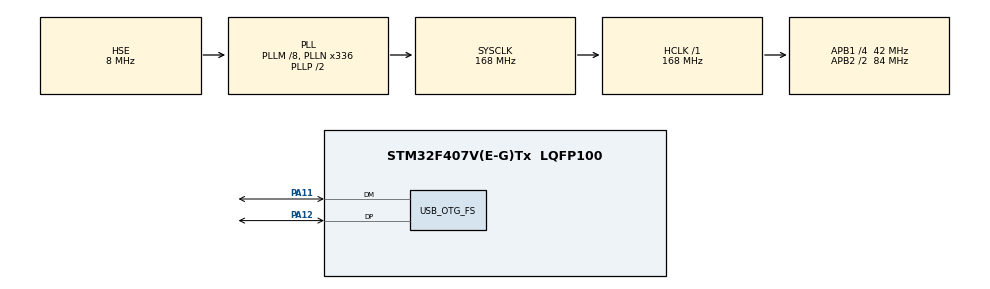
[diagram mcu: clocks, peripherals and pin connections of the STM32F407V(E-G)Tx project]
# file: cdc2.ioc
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Mcu.Family=STM32F4
Mcu.Name=STM32F407V(E-G)Tx
Mcu.Package=LQFP100
NVIC.OTG_FS_IRQn=true\:0\:0\:false\:false\:true\:true\:true
NVIC.PriorityGroup=NVIC_PRIORITYGROUP_0
PA11.Mode=Device_Only
PA11.Signal=USB_OTG_FS_DM
PA12.Mode=Device_Only
PA12.Signal=USB_OTG_FS_DP
PH0-OSC_IN.Mode=HSE-External-Oscillator
PH0-OSC_IN.Signal=RCC_OSC_IN
PH1-OSC_OUT.Mode=HSE-External-Oscillator
PH1-OSC_OUT.Signal=RCC_OSC_OUT
ProjectManager.HeapSize=0x400
ProjectManager.StackSize=0x600
ProjectManager.TargetToolchain=STM32CubeIDE
RCC.48MHZClocksFreq_Value=48000000
RCC.AHBFreq_Value=168000000
RCC.APB1CLKDivider=RCC_HCLK_DIV4
RCC.APB1Freq_Value=42000000
RCC.APB1TimFreq_Value=84000000
RCC.APB2CLKDivider=RCC_HCLK_DIV2
RCC.APB2Freq_Value=84000000
RCC.APB2TimFreq_Value=168000000
RCC.CortexFreq_Value=168000000
RCC.HCLKFreq_Value=168000000
RCC.HSE_VALUE=8000000
RCC.HSI_VALUE=16000000
RCC.PLLM=8
RCC.PLLN=336
RCC.PLLQ=7
RCC.SYSCLKFreq_VALUE=168000000
RCC.SYSCLKSource=RCC_SYSCLKSOURCE_PLLCLK
RCC.VCOOutputFreq_Value=336000000
USB_DEVICE.CLASS_NAME_FS=CDC
USB_DEVICE.VirtualMode-CDC_FS=Cdc
USB_DEVICE.VirtualModeFS=Cdc_FS
USB_OTG_FS.VirtualMode=Device_Only
VP_USB_DEVICE_VS_USB_DEVICE_CDC_FS.Mode=CDC_FS
board=STM32F407G-DISC1

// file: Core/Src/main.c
/* USER CODE BEGIN Header */
/**
  ******************************************************************************
  * @file           : main.c
  * @brief          : Main program body
  ******************************************************************************
  * @attention
  *
  * <h2><center>&copy; Copyright (c) 2020 STMicroelectronics.
  * All rights reserved.</center></h2>
  *
  * This software component is licensed by ST under Ultimate Liberty license
  * SLA0044, the "License"; You may not use this file except in compliance with
  * the License. You may obtain a copy of the License at:
  *                             www.st.com/SLA0044
  *
  ******************************************************************************
  */
/* USER CODE END Header */
#include "main.h"
#include "usb_device.h"
#include "ringbuffer.h"

/* USER CODE BEGIN Includes */
#include <string.h>

#include "usbd_cdc_if.h"
/* USER CODE END Includes */

void SystemClock_Config(void);
static void MX_GPIO_Init(void);

/* USER CODE BEGIN 0 */
uint8_t Buf[20]="momo world\r\n";

RingBuffer txBuf, rxBuf;
uint8_t  *txData;

/* USER CODE END 0 */

int main(void)
{

  /* MCU Configuration--------------------------------------------------------*/

  /* Reset of all peripherals, Initializes the Flash interface and the Systick. */
  HAL_Init();

  /* Configure the system clock */
  SystemClock_Config();

  /* Initialize all configured peripherals */
  MX_GPIO_Init();
  MX_USB_DEVICE_Init();
  /* USER CODE BEGIN 2 */
  uint8_t Buf2[20]="E.t rulezz\r\n";
  uint8_t Buf3[20]="Hail E.t\r\n";
  /* USER CODE END 2 */

  /* Infinite loop */
  while (1)
  {
   // CDC_Transmit_FS(Buf, strlen(Buf));
	  myusbttransmit(Buf, strlen(Buf));

  HAL_Delay(50);

	 myusbttransmit(Buf2, strlen(Buf2));

 HAL_Delay(50);
 myusbttransmit(Buf3, strlen(Buf3));
 HAL_Delay(50);

  }
}

void SystemClock_Config(void)
{
  RCC_OscInitTypeDef RCC_OscInitStruct = {0};
  RCC_ClkInitTypeDef RCC_ClkInitStruct = {0};

  /** Configure the main internal regulator output voltage
  */
  __HAL_RCC_PWR_CLK_ENABLE();
  __HAL_PWR_VOLTAGESCALING_CONFIG(PWR_REGULATOR_VOLTAGE_SCALE1);
  /** Initializes the RCC Oscillators according to the specified parameters
  * in the RCC_OscInitTypeDef structure.
  */
  RCC_OscInitStruct.OscillatorType = RCC_OSCILLATORTYPE_HSE;
  RCC_OscInitStruct.HSEState = RCC_HSE_ON;
  RCC_OscInitStruct.PLL.PLLState = RCC_PLL_ON;
  RCC_OscInitStruct.PLL.PLLSource = RCC_PLLSOURCE_HSE;
  RCC_OscInitStruct.PLL.PLLM = 8;
  RCC_OscInitStruct.PLL.PLLN = 336;
  RCC_OscInitStruct.PLL.PLLP = RCC_PLLP_DIV2;
  RCC_OscInitStruct.PLL.PLLQ = 7;
  if (HAL_RCC_OscConfig(&RCC_OscInitStruct) != HAL_OK)
  {
    Error_Handler();
  }
  /** Initializes the CPU, AHB and APB buses clocks
  */
  RCC_ClkInitStruct.ClockType = RCC_CLOCKTYPE_HCLK|RCC_CLOCKTYPE_SYSCLK
                              |RCC_CLOCKTYPE_PCLK1|RCC_CLOCKTYPE_PCLK2;
  RCC_ClkInitStruct.SYSCLKSource = RCC_SYSCLKSOURCE_PLLCLK;
  RCC_ClkInitStruct.AHBCLKDivider = RCC_SYSCLK_DIV1;
  RCC_ClkInitStruct.APB1CLKDivider = RCC_HCLK_DIV4;
  RCC_ClkInitStruct.APB2CLKDivider = RCC_HCLK_DIV2;

  if (HAL_RCC_ClockConfig(&RCC_ClkInitStruct, FLASH_LATENCY_5) != HAL_OK)
  {
    Error_Handler();
  }
}

static void MX_GPIO_Init(void)
{

  /* GPIO Ports Clock Enable */
  __HAL_RCC_GPIOH_CLK_ENABLE();
  __HAL_RCC_GPIOA_CLK_ENABLE();

}

/* USER CODE BEGIN 4 */
void myusbttransmit(uint8_t* pData, uint16_t Len)
{
	if (CDC_Transmit_FS(pData, strlen(pData))!=USBD_OK)
	{
		if(RingBuffer_Write(&txBuf, pData, strlen(pData)) != RING_BUFFER_OK)
		{
		return 0;
		}

	}
	return 1;
}
 void mynonstatictxcomplete()
 {
	 if(RingBuffer_GetDataLength(&txBuf) > 0) {
	 	 RingBuffer_Read(&txBuf, txData, 1);
	 	CDC_Transmit_FS(txData, strlen(*txData));
	 	 }

 }
/* USER CODE END 4 */

void Error_Handler(void)
{
  __disable_irq();
  while (1)
  {
  }
}

/************************ (C) COPYRIGHT STMicroelectronics *****END OF FILE****/
